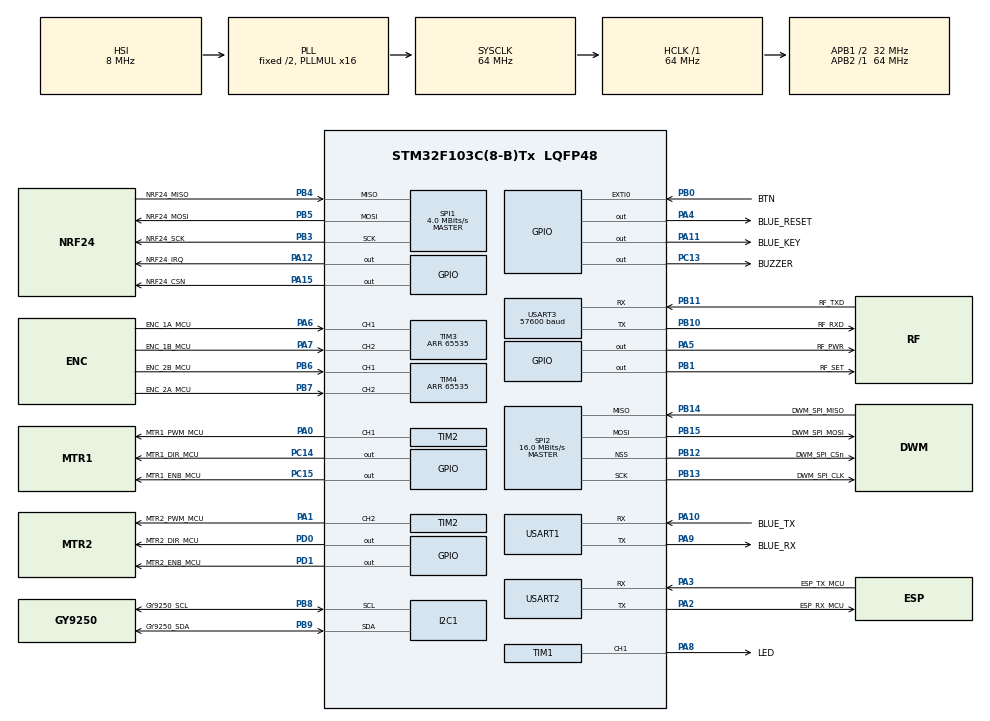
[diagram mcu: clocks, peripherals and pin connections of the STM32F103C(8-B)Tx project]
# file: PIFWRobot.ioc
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Dma.Request0=USART3_RX
Dma.Request1=USART3_TX
Dma.Request2=USART2_RX
Dma.Request3=USART2_TX
Dma.USART2_RX.2.Direction=DMA_PERIPH_TO_MEMORY
Dma.USART2_RX.2.Instance=DMA1_Channel6
Dma.USART2_RX.2.MemDataAlignment=DMA_MDATAALIGN_BYTE
Dma.USART2_RX.2.MemInc=DMA_MINC_ENABLE
Dma.USART2_RX.2.Mode=DMA_NORMAL
Dma.USART2_RX.2.PeriphDataAlignment=DMA_PDATAALIGN_BYTE
Dma.USART2_RX.2.PeriphInc=DMA_PINC_DISABLE
Dma.USART2_RX.2.Priority=DMA_PRIORITY_LOW
Dma.USART2_TX.3.Direction=DMA_MEMORY_TO_PERIPH
Dma.USART2_TX.3.Instance=DMA1_Channel7
Dma.USART2_TX.3.MemDataAlignment=DMA_MDATAALIGN_BYTE
Dma.USART2_TX.3.MemInc=DMA_MINC_ENABLE
Dma.USART2_TX.3.Mode=DMA_NORMAL
Dma.USART2_TX.3.PeriphDataAlignment=DMA_PDATAALIGN_BYTE
Dma.USART2_TX.3.PeriphInc=DMA_PINC_DISABLE
Dma.USART2_TX.3.Priority=DMA_PRIORITY_LOW
Dma.USART3_RX.0.Direction=DMA_PERIPH_TO_MEMORY
Dma.USART3_RX.0.Instance=DMA1_Channel3
Dma.USART3_RX.0.MemDataAlignment=DMA_MDATAALIGN_BYTE
Dma.USART3_RX.0.MemInc=DMA_MINC_ENABLE
Dma.USART3_RX.0.Mode=DMA_NORMAL
Dma.USART3_RX.0.PeriphDataAlignment=DMA_PDATAALIGN_BYTE
Dma.USART3_RX.0.PeriphInc=DMA_PINC_DISABLE
Dma.USART3_RX.0.Priority=DMA_PRIORITY_LOW
Dma.USART3_TX.1.Direction=DMA_MEMORY_TO_PERIPH
Dma.USART3_TX.1.Instance=DMA1_Channel2
Dma.USART3_TX.1.MemDataAlignment=DMA_MDATAALIGN_BYTE
Dma.USART3_TX.1.MemInc=DMA_MINC_ENABLE
Dma.USART3_TX.1.Mode=DMA_NORMAL
Dma.USART3_TX.1.PeriphDataAlignment=DMA_PDATAALIGN_BYTE
Dma.USART3_TX.1.PeriphInc=DMA_PINC_DISABLE
Dma.USART3_TX.1.Priority=DMA_PRIORITY_LOW
I2C1.I2C_Mode=I2C_Fast
Mcu.Family=STM32F1
Mcu.Name=STM32F103C(8-B)Tx
Mcu.Package=LQFP48
NVIC.DMA1_Channel2_IRQn=true\:0\:0\:false\:false\:true\:false\:true
NVIC.DMA1_Channel3_IRQn=true\:0\:0\:false\:false\:true\:false\:true
NVIC.DMA1_Channel6_IRQn=true\:0\:0\:false\:false\:true\:false\:true
NVIC.DMA1_Channel7_IRQn=true\:0\:0\:false\:false\:true\:false\:true
NVIC.PriorityGroup=NVIC_PRIORITYGROUP_4
NVIC.TIM1_UP_IRQn=true\:15\:0\:true\:false\:true\:true\:true
NVIC.USART2_IRQn=true\:0\:0\:false\:false\:true\:true\:true
NVIC.USART3_IRQn=true\:0\:0\:false\:false\:true\:true\:true
PA0-WKUP.GPIO_Label=MTR1_PWM_MCU
PA0-WKUP.Signal=S_TIM2_CH1_ETR
PA1.GPIO_Label=MTR2_PWM_MCU
PA1.Signal=S_TIM2_CH2
PA10.GPIO_Label=BLUE_TX
PA10.Mode=Asynchronous
PA10.Signal=USART1_RX
PA11.GPIO_Label=BLUE_KEY
PA11.Signal=GPIO_Output
PA12.GPIO_Label=NRF24_IRQ
PA12.Signal=GPIO_Output
PA13.Mode=Serial_Wire
PA13.Signal=SYS_JTMS-SWDIO
PA14.Mode=Serial_Wire
PA14.Signal=SYS_JTCK-SWCLK
PA15.GPIO_Label=NRF24_CSN
PA15.Signal=GPIO_Output
PA2.GPIO_Label=ESP_RX_MCU
PA2.Mode=Asynchronous
PA2.Signal=USART2_TX
PA3.GPIO_Label=ESP_TX_MCU
PA3.Mode=Asynchronous
PA3.Signal=USART2_RX
PA4.GPIO_Label=BLUE_RESET
PA4.Signal=GPIO_Output
PA5.GPIO_Label=RF_PWR
PA5.Signal=GPIO_Output
PA6.GPIO_Label=ENC_1A_MCU
PA6.Signal=S_TIM3_CH1
PA7.GPIO_Label=ENC_1B_MCU
PA7.Signal=S_TIM3_CH2
PA8.GPIO_Label=LED
PA8.Signal=S_TIM1_CH1
PA9.GPIO_Label=BLUE_RX
PA9.Mode=Asynchronous
PA9.Signal=USART1_TX
PB0.GPIO_Label=BTN
PB0.Signal=GPXTI0
PB1.GPIO_Label=RF_SET
PB1.Signal=GPIO_Output
PB10.GPIO_Label=RF_RXD
PB10.Mode=Asynchronous
PB10.Signal=USART3_TX
PB11.GPIO_Label=RF_TXD
PB11.Mode=Asynchronous
PB11.Signal=USART3_RX
PB12.GPIO_Label=DWM_SPI_CSn
PB12.Mode=NSS_Signal_Hard_Output
PB12.Signal=SPI2_NSS
PB13.GPIO_Label=DWM_SPI_CLK
PB13.Mode=Full_Duplex_Master
PB13.Signal=SPI2_SCK
PB14.GPIO_Label=DWM_SPI_MISO
PB14.Mode=Full_Duplex_Master
PB14.Signal=SPI2_MISO
PB15.GPIO_Label=DWM_SPI_MOSI
PB15.Mode=Full_Duplex_Master
PB15.Signal=SPI2_MOSI
PB3.GPIO_Label=NRF24_SCK
PB3.Mode=Full_Duplex_Master
PB3.Signal=SPI1_SCK
PB4.GPIO_Label=NRF24_MISO
PB4.Mode=Full_Duplex_Master
PB4.Signal=SPI1_MISO
PB5.GPIO_Label=NRF24_MOSI
PB5.Mode=Full_Duplex_Master
PB5.Signal=SPI1_MOSI
PB6.GPIO_Label=ENC_2B_MCU
PB6.Signal=S_TIM4_CH1
PB7.GPIO_Label=ENC_2A_MCU
PB7.Signal=S_TIM4_CH2
PB8.GPIO_Label=GY9250_SCL
PB8.Mode=I2C
PB8.Signal=I2C1_SCL
PB9.GPIO_Label=GY9250_SDA
PB9.Mode=I2C
PB9.Signal=I2C1_SDA
PC13-TAMPER-RTC.GPIO_Label=BUZZER
PC13-TAMPER-RTC.Signal=GPIO_Output
PC14-OSC32_IN.GPIO_Label=MTR1_DIR_MCU
PC14-OSC32_IN.Signal=GPIO_Output
PC15-OSC32_OUT.GPIO_Label=MTR1_ENB_MCU
PC15-OSC32_OUT.Signal=GPIO_Output
PD0-OSC_IN.GPIO_Label=MTR2_DIR_MCU
PD0-OSC_IN.Signal=GPIO_Output
PD1-OSC_OUT.GPIO_Label=MTR2_ENB_MCU
PD1-OSC_OUT.Signal=GPIO_Output
ProjectManager.HeapSize=0x200
ProjectManager.StackSize=0x400
ProjectManager.TargetToolchain=STM32CubeIDE
RCC.AHBFreq_Value=64000000
RCC.APB1CLKDivider=RCC_HCLK_DIV2
RCC.APB1Freq_Value=32000000
RCC.APB1TimFreq_Value=64000000
RCC.APB2Freq_Value=64000000
RCC.APB2TimFreq_Value=64000000
RCC.HCLKFreq_Value=64000000
RCC.PLLMUL=RCC_PLL_MUL16
RCC.SYSCLKFreq_VALUE=64000000
RCC.SYSCLKSource=RCC_SYSCLKSOURCE_PLLCLK
RCC.USBFreq_Value=42666666.666666664
RCC.USBPrescaler=RCC_USBCLKSOURCE_PLL_DIV1_5
SH.S_TIM1_CH1.0=TIM1_CH1,PWM Generation1 CH1
SH.S_TIM2_CH1_ETR.0=TIM2_CH1,PWM Generation1 CH1
SH.S_TIM2_CH2.0=TIM2_CH2,PWM Generation2 CH2
SH.S_TIM3_CH1.0=TIM3_CH1,Encoder_Interface
SH.S_TIM3_CH2.0=TIM3_CH2,Encoder_Interface
SH.S_TIM4_CH1.0=TIM4_CH1,Encoder_Interface
SH.S_TIM4_CH2.0=TIM4_CH2,Encoder_Interface
SPI1.BaudRatePrescaler=SPI_BAUDRATEPRESCALER_16
SPI1.CalculateBaudRate=4.0 MBits/s
SPI1.Direction=SPI_DIRECTION_2LINES
SPI1.Mode=SPI_MODE_MASTER
SPI1.VirtualType=VM_MASTER
SPI2.CalculateBaudRate=16.0 MBits/s
SPI2.Direction=SPI_DIRECTION_2LINES
SPI2.Mode=SPI_MODE_MASTER
SPI2.VirtualNSS=VM_NSSHARD
SPI2.VirtualType=VM_MASTER
TIM1.Channel-PWM\ Generation1\ CH1=TIM_CHANNEL_1
TIM1.Period=80-1
TIM1.Prescaler=0
TIM2.Channel-PWM\ Generation1\ CH1=TIM_CHANNEL_1
TIM2.Channel-PWM\ Generation2\ CH2=TIM_CHANNEL_2
TIM2.Period=999
TIM2.Prescaler=0
TIM3.Period=65535
TIM4.Period=65535
USART1.VirtualMode=VM_ASYNC
USART2.VirtualMode=VM_ASYNC
USART3.BaudRate=57600
USART3.VirtualMode=VM_ASYNC
VP_TIM1_VS_ClockSourceINT.Mode=Internal
VP_TIM2_VS_ClockSourceINT.Mode=Internal
board=custom

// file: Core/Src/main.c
/* USER CODE BEGIN Header */
/**
  ******************************************************************************
  * @file           : main.c
  * @brief          : Main program body
  ******************************************************************************
  * @attention
  *
  * <h2><center>&copy; Copyright (c) 2021 STMicroelectronics.
  * All rights reserved.</center></h2>
  *
  * This software component is licensed by ST under BSD 3-Clause license,
  * the "License"; You may not use this file except in compliance with the
  * License. You may obtain a copy of the License at:
  *                        opensource.org/licenses/BSD-3-Clause
  *
  ******************************************************************************
  */
/* USER CODE END Header */
#include "main.h"
#include "dma.h"
#include "i2c.h"
#include "spi.h"
#include "tim.h"
#include "usart.h"
#include "gpio.h"

/* USER CODE BEGIN Includes */
#include "application/app_main.h"
/* USER CODE END Includes */

void SystemClock_Config(void);

int main(void)
{

  /* MCU Configuration--------------------------------------------------------*/

  /* Reset of all peripherals, Initializes the Flash interface and the Systick. */
  HAL_Init();

  /* Configure the system clock */
  SystemClock_Config();

  /* Initialize all configured peripherals */
  MX_GPIO_Init();
  MX_I2C1_Init();
  MX_USART3_UART_Init();
  MX_DMA_Init();
  MX_SPI1_Init();
  MX_SPI2_Init();
  MX_TIM2_Init();
  MX_TIM3_Init();
  MX_TIM4_Init();
  MX_USART1_UART_Init();
  MX_USART2_UART_Init();
  MX_TIM1_Init();
  /* USER CODE BEGIN 2 */
  app_main();
  /* USER CODE END 2 */

  /* Infinite loop */
  while (1)
  {

  }
}

void SystemClock_Config(void)
{
  RCC_OscInitTypeDef RCC_OscInitStruct = {0};
  RCC_ClkInitTypeDef RCC_ClkInitStruct = {0};

  /** Initializes the RCC Oscillators according to the specified parameters
  * in the RCC_OscInitTypeDef structure.
  */
  RCC_OscInitStruct.OscillatorType = RCC_OSCILLATORTYPE_HSI;
  RCC_OscInitStruct.HSIState = RCC_HSI_ON;
  RCC_OscInitStruct.HSICalibrationValue = RCC_HSICALIBRATION_DEFAULT;
  RCC_OscInitStruct.PLL.PLLState = RCC_PLL_ON;
  RCC_OscInitStruct.PLL.PLLSource = RCC_PLLSOURCE_HSI_DIV2;
  RCC_OscInitStruct.PLL.PLLMUL = RCC_PLL_MUL16;
  if (HAL_RCC_OscConfig(&RCC_OscInitStruct) != HAL_OK)
  {
    Error_Handler();
  }
  /** Initializes the CPU, AHB and APB buses clocks
  */
  RCC_ClkInitStruct.ClockType = RCC_CLOCKTYPE_HCLK|RCC_CLOCKTYPE_SYSCLK
                              |RCC_CLOCKTYPE_PCLK1|RCC_CLOCKTYPE_PCLK2;
  RCC_ClkInitStruct.SYSCLKSource = RCC_SYSCLKSOURCE_PLLCLK;
  RCC_ClkInitStruct.AHBCLKDivider = RCC_SYSCLK_DIV1;
  RCC_ClkInitStruct.APB1CLKDivider = RCC_HCLK_DIV2;
  RCC_ClkInitStruct.APB2CLKDivider = RCC_HCLK_DIV1;

  if (HAL_RCC_ClockConfig(&RCC_ClkInitStruct, FLASH_LATENCY_2) != HAL_OK)
  {
    Error_Handler();
  }
}

void Error_Handler(void)
{
  __disable_irq();
  while (1)
  {
  }
}

/************************ (C) COPYRIGHT STMicroelectronics *****END OF FILE****/
